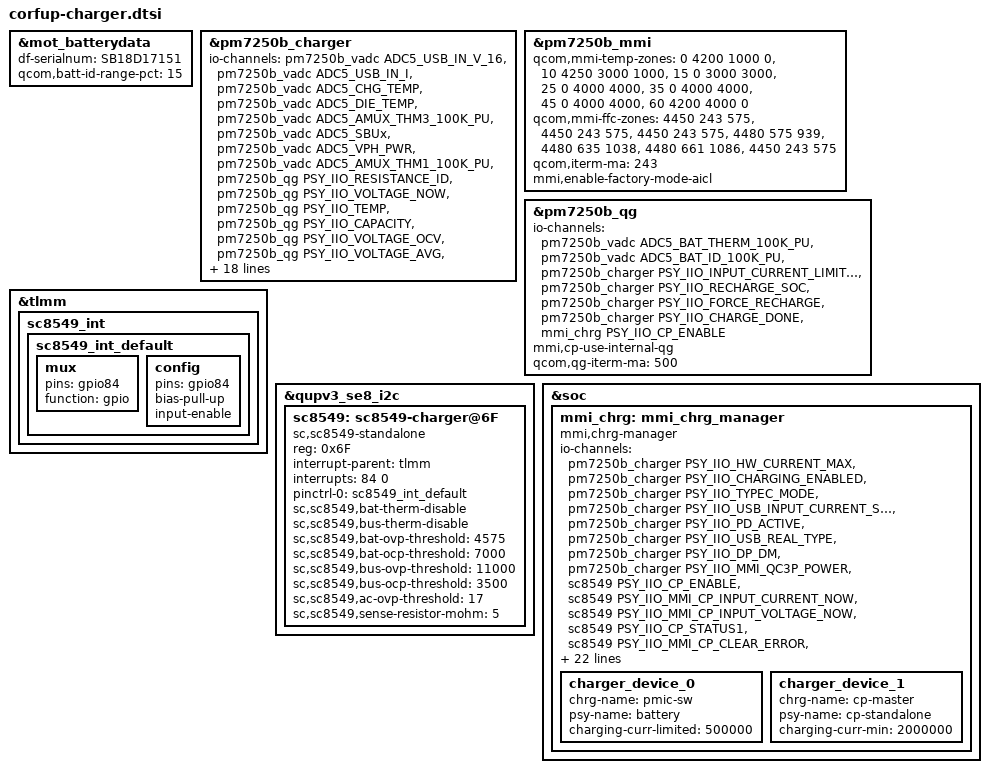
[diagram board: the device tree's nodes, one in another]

#include <dt-bindings/iio/qti_power_supply_iio.h>


&mot_batterydata {
	df-serialnum = "SB18D17151";
	qcom,batt-id-range-pct = <15>;
	#include "qg-batterydata-ng50-atl-5000mah.dtsi"
	#include "qg-batterydata-ng50-swd-5000mah.dtsi"
};

&pm7250b_charger {
	#io-channel-cells = <1>;
	io-channels = <&pm7250b_vadc ADC5_USB_IN_V_16>,
		      <&pm7250b_vadc ADC5_USB_IN_I>,
		      <&pm7250b_vadc ADC5_CHG_TEMP>,
		      <&pm7250b_vadc ADC5_DIE_TEMP>,
		      <&pm7250b_vadc ADC5_AMUX_THM3_100K_PU>,
		      <&pm7250b_vadc ADC5_SBUx>,
		      <&pm7250b_vadc ADC5_VPH_PWR>,
		      <&pm7250b_vadc ADC5_AMUX_THM1_100K_PU>,
		      <&pm7250b_qg PSY_IIO_RESISTANCE_ID>,
		      <&pm7250b_qg PSY_IIO_VOLTAGE_NOW>,
		      <&pm7250b_qg PSY_IIO_TEMP>,
		      <&pm7250b_qg PSY_IIO_CAPACITY>,
		      <&pm7250b_qg PSY_IIO_VOLTAGE_OCV>,
		      <&pm7250b_qg PSY_IIO_VOLTAGE_AVG>,
		      <&pm7250b_qg PSY_IIO_DEBUG_BATTERY>,
		      <&pm7250b_qg PSY_IIO_REAL_CAPACITY>,
		      <&pm7250b_qg PSY_IIO_CC_SOC>,
		      <&pm7250b_qg PSY_IIO_CURRENT_NOW>,
		      <&pm7250b_qg PSY_IIO_VOLTAGE_MAX>,
		      <&pm7250b_qg PSY_IIO_CHARGE_FULL>,
		      <&pm7250b_qg PSY_IIO_CHARGE_COUNTER>,
		      <&pm7250b_qg PSY_IIO_CYCLE_COUNT>,
		      <&pm7250b_qg PSY_IIO_CHARGE_FULL_DESIGN>,
		      <&pm7250b_qg PSY_IIO_TIME_TO_FULL_NOW>,
                      <&sc8549 PSY_IIO_MMI_CP_INPUT_VOLTAGE_NOW>;
	io-channel-names = "usb_in_voltage",
			   "usb_in_current",
			   "chg_temp",
			   "die_temp",
			   "conn_temp",
			   "sbux_res",
			   "vph_voltage",
			   "skin_temp",
			   "resistance_id",
			   "voltage_now",
			   "temp",
			   "capacity",
			   "voltage_ocv",
			   "voltage_avg",
			   "debug_battery",
			   "real_capacity",
			   "cc_soc",
			   "current_now",
			   "voltage_max",
			   "charge_full",
			   "charge_counter",
			   "cycle_count",
			   "charge_full_design",
			   "time_to_full_now",
			   "cp_input_voltage_now";
	qcom,fcc-max-ua = <3000000>;
	qcom,fv-max-uv = <4480000>;
	qcom,dcp-curr-max = <1500000>;
	qcom,otg-cl-ua = <1000000>;
	qcom,thermal-mitigation = <3000000 2500000
			2000000 1500000
			1200000 900000
			600000>;
	mmi,qc3p-support;
	/delete-property/ qcom,fcc-stepping-enable;

};

&pm7250b_mmi {
	qcom,mmi-temp-zones = <0 4200 1000 0>,
				<10 4250 3000 1000>,
				<15 0 3000 3000>,
				<25 0 4000 4000>,
				<35 0 4000 4000>,
				<45 0 4000 4000>,
				<60 4200 4000 0>;
	qcom,mmi-ffc-zones = <4450 243 575>,
                               <4450 243 575>,
                               <4450 243 575>,
                               <4480 575 939>,
                               <4480 635 1038>,
                               <4480 661 1086>,
                               <4450 243 575>;

	qcom,iterm-ma = <243>;
	mmi,enable-factory-mode-aicl;
};


&pm7250b_qg {
	#io-channel-cells = <1>;
	io-channels = <&pm7250b_vadc ADC5_BAT_THERM_100K_PU>,
		      <&pm7250b_vadc ADC5_BAT_ID_100K_PU>,
		      <&pm7250b_charger PSY_IIO_INPUT_CURRENT_LIMITED>,
		      <&pm7250b_charger PSY_IIO_RECHARGE_SOC>,
		      <&pm7250b_charger PSY_IIO_FORCE_RECHARGE>,
		      <&pm7250b_charger PSY_IIO_CHARGE_DONE>,
		      <&mmi_chrg PSY_IIO_CP_ENABLE>;
	io-channel-names = "batt-therm",
			   "batt-id",
			   "input_current_limited",
			   "recharge_soc",
			   "force_recharge",
			   "charge_done",
			   "cp_charging_enabled";
	mmi,cp-use-internal-qg;
	qcom,qg-iterm-ma = <500>;
};

&tlmm {
	sc8549_int {
		sc8549_int_default: sc8549_int_default {
			mux {
				pins = "gpio84";
				function = "gpio";
			};

			config {
				pins = "gpio84";
				bias-pull-up;         /* PULL UP */
				input-enable;
			};
		};
	};
};

&qupv3_se8_i2c {
	status = "okay";

	sc8549: sc8549-charger@6F{
		compatible = "sc,sc8549-standalone";
		#io-channel-cells = <1>;
		reg = <0x6F>;
		interrupt-parent = <&tlmm>;
		interrupts = <84 0>;
		pinctrl-names = "default";
		pinctrl-0 = <&sc8549_int_default>;
		/*sc,sc8549,bat-ovp-disable;
		sc,sc8549,bat-ocp-disable;
		sc,sc8549,bus-ocp-disable;
		sc,sc8549,bus-ovp-disable;*/
		sc,sc8549,bat-therm-disable;
		sc,sc8549,bus-therm-disable;

		sc,sc8549,bat-ovp-threshold = <4575>;
		sc,sc8549,bat-ocp-threshold = <7000>;

		sc,sc8549,bus-ovp-threshold = <11000>;
		sc,sc8549,bus-ocp-threshold = <3500>;

		sc,sc8549,ac-ovp-threshold = <17>;
		sc,sc8549,sense-resistor-mohm = <5>;
	};
};

&soc {
	mmi_chrg: mmi_chrg_manager {
		compatible = "mmi,chrg-manager";
		#io-channel-cells = <1>;
		io-channels = <&pm7250b_charger PSY_IIO_HW_CURRENT_MAX>,
				<&pm7250b_charger PSY_IIO_CHARGING_ENABLED>,
				<&pm7250b_charger PSY_IIO_TYPEC_MODE>,
				<&pm7250b_charger PSY_IIO_USB_INPUT_CURRENT_SETTLED>,
				<&pm7250b_charger PSY_IIO_PD_ACTIVE>,
				/*qc3p start*/
                               <&pm7250b_charger PSY_IIO_USB_REAL_TYPE>,
                               <&pm7250b_charger PSY_IIO_DP_DM>,
                               <&pm7250b_charger PSY_IIO_MMI_QC3P_POWER>,
                               /*qc3p end*/
				<&sc8549 PSY_IIO_CP_ENABLE>,
				<&sc8549 PSY_IIO_MMI_CP_INPUT_CURRENT_NOW>,
				<&sc8549 PSY_IIO_MMI_CP_INPUT_VOLTAGE_NOW>,
				<&sc8549 PSY_IIO_CP_STATUS1>,
				<&sc8549 PSY_IIO_MMI_CP_CLEAR_ERROR>,
				<&pm7250b_mmi PSY_IIO_CP_ENABLE>;


		io-channel-names = "usb_hw_current_max",
					"charging_enabled",
					"usb_typec_mode",
					"usb_input_current_settled",
					"usb_pd_active",
					/*qc3p start*/
                                        "usb_real_type",
                                        "battery_dp_dm",
                                        "usb_qc3p_power",
                                        /*qc3p end*/
					"cp_enable",
					"cp_input_current_now",
					"cp_input_voltage_now",
					"cp_status1",
					"cp_clear_error",
					"mmi_cp_enabled_status";

		qcom,usbpd-phandle = <&pm7250b_pdphy>;
		mmi,pps-volt-steps = <20000>;
		mmi,pps-curr-steps = <100000>;
		mmi,pd-volt-max = <10000000>;
		mmi,pd-curr-max = <3000000>;
		mmi,batt-curr-boost = <300000>;
		mmi,batt-ovp-lmt = <4550000>;
		mmi,pl-chrg-vbatt-min = <3600000>;
		mmi,typec-middle-current = <2000000>;
		mmi,pd-allow-min-current = <1000000>;
		mmi,step-first-current-comp = <0>;
		mmi,dont-rerun-aicl;
		/*qc3p start*/
		mmi,qc3p-max-ibus-ma = <3000>;
                mmi,qc3p-volt-steps = <20000>;
                mmi,qc3p-volt-max = <10000000>;
                /*qc3p end*/
		mmi,chrg-temp-zones-num = <5>;
		mmi,mmi-chrg-temp-zones =
					<0 4200 1000  0 0>,
					<10 4250 3000 4450 1000>,
					<15 4450 3000 0 0>,
					<45 4350 5800 4480 4000>,
					<60 4200 4000 0 0>;
		mmi,thermal-mitigation =
					<5800000>,
					<5000000>,
					<4000000>,
					<3500000>,
					<3000000>,
					<2000000>,
					<1000000>;
		charger_device_0 {
			chrg-name = "pmic-sw";
			psy-name = "battery";
			charging-curr-limited = <500000>;
		};
		charger_device_1 {
			chrg-name = "cp-master";
			psy-name = "cp-standalone";
			charging-curr-min = <2000000>;
		};
	};
};

